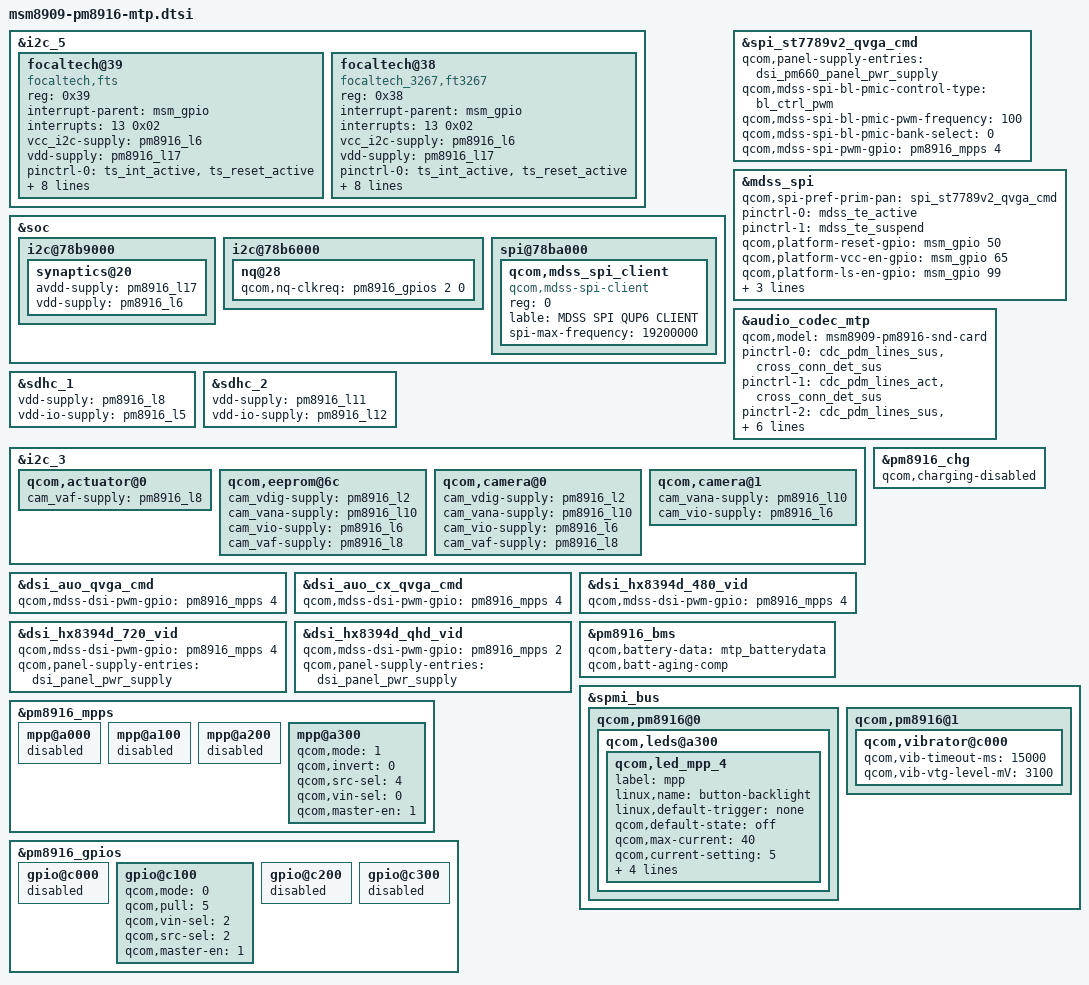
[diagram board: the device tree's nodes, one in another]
/*
 * Copyright (c) 2014-2017, The Linux Foundation. All rights reserved.
 *
 * This program is free software; you can redistribute it and/or modify
 * it under the terms of the GNU General Public License version 2 and
 * only version 2 as published by the Free Software Foundation.
 *
 * This program is distributed in the hope that it will be useful,
 * but WITHOUT ANY WARRANTY; without even the implied warranty of
 * MERCHANTABILITY or FITNESS FOR A PARTICULAR PURPOSE.  See the
 * GNU General Public License for more details.
 */

/*[Arima_4101][allen_yu] LightPhone ft3417 touch driver porting and dynamic detect ft3267 and ft3417 20181227 begin*/
/*[Arima_4101][allen_yu] LightPhone ft3267 touch driver porting 20180906 begin*/
&i2c_5 {
	status = "ok";
	focaltech@39 {
		compatible = "focaltech,fts";
		reg = <0x39>;
		interrupt-parent = <&msm_gpio>;
		interrupts = <13 0x02>;
		vcc_i2c-supply = <&pm8916_l6>;
		vdd-supply = <&pm8916_l17>;
		//focaltech,vcc_i2c-voltage = <1800000 1800000>;
		//focaltech,vdd-voltage = <2600000 3300000>;
		//focaltech,vcc_i2c-current = <40000>;
		//focaltech,vdd-current = <20000>;
		/* pins used by touchscreen */
		pinctrl-names = "pmx_ts_active", "pmx_ts_suspend",
			"pmx_ts_release";
		pinctrl-0 = <&ts_int_active &ts_reset_active>;
		pinctrl-1 = <&ts_int_suspend &ts_reset_suspend>;
		pinctrl-2 = <&ts_release>;
		focaltech,display-coords = <0 0 480 600>;
		focaltech,panel-coords = <0 0 480 600>;
		focaltech,irq-gpio = <&msm_gpio 13 0x02>;
		focaltech,reset-gpio = <&msm_gpio 25 0x01>;
		focaltech,max-touch-number = <5>;
		focaltech,i2c-pull-up;
		//focaltech,disable-gpios;
		//focaltech,button-map = <139 172 158>;
		};
};


&i2c_5 {
	status = "ok";
	focaltech@38 {
		compatible = "focaltech_3267,ft3267";
		reg = <0x38>;
		interrupt-parent = <&msm_gpio>;
		interrupts = <13 0x02>;
		vcc_i2c-supply = <&pm8916_l6>;
		vdd-supply = <&pm8916_l17>;
		//focaltech,vcc_i2c-voltage = <1800000 1800000>;
		//focaltech,vdd-voltage = <2600000 3300000>;
		//focaltech,vcc_i2c-current = <40000>;
		//focaltech,vdd-current = <20000>;
		/* pins used by touchscreen */
		pinctrl-names = "pmx_ts_active", "pmx_ts_suspend",
			"pmx_ts_release";
		pinctrl-0 = <&ts_int_active &ts_reset_active>;
		pinctrl-1 = <&ts_int_suspend &ts_reset_suspend>;
		pinctrl-2 = <&ts_release>;
/*[Arima_4101][allen_yu] Modify LCM/TP resolution 20181121 begin*/
		focaltech,display-coords = <0 0 480 600>;
		focaltech,panel-coords = <0 0 480 600>;
/*[Arima_4101][allen_yu] 20181121 end*/
		focaltech,irq-gpio = <&msm_gpio 13 0x02>;
		focaltech,reset-gpio = <&msm_gpio 25 0x01>;
/*[Arima_4101][allen_yu] Upgrade focaltech touch firmware to V12 20181017 begin*/
/*[Arima_4101][allen_yu] Fix multi touch issue(change protocal from B to A) 20181015 begin*/
		focaltech,max-touch-number = <1>;
/*[Arima_4101][allen_yu] 20181015 end*/
/*[Arima_4101][allen_yu] 20181017 end*/
		focaltech,i2c-pull-up;
		//focaltech,disable-gpios;
		//focaltech,button-map = <139 172 158>;
		};
};
/*[Arima_4101][allen_yu] 20180906 end*/
/*[Arima_4101][allen_yu] 20181227 end*/

&soc {
	i2c@78b9000 {
		synaptics@20 {
			avdd-supply = <&pm8916_l17>;
			vdd-supply = <&pm8916_l6>;
		};
	};

	i2c@78b6000 {
		nq@28 {
			qcom,nq-clkreq = <&pm8916_gpios 2 0>;
		};
	};

	spi@78ba000 {
		status = "ok";
		qcom,mdss_spi_client {
			reg = <0>;
			compatible = "qcom,mdss-spi-client";
			lable = "MDSS SPI QUP6 CLIENT";
			//spi-max-frequency = <50000000>;
			spi-max-frequency = <19200000>;
			//spi-cpha;
		};
	};
};

&spi_st7789v2_qvga_cmd {
		qcom,panel-supply-entries = <&dsi_pm660_panel_pwr_supply>;
		qcom,mdss-spi-bl-pmic-control-type = "bl_ctrl_pwm";
		qcom,mdss-spi-bl-pmic-pwm-frequency = <100>;
		qcom,mdss-spi-bl-pmic-bank-select = <0>;
		qcom,mdss-spi-pwm-gpio = <&pm8916_mpps 4 0>;
		/*qcom,cont-splash-enabled;*/
	};

&mdss_spi {
		qcom,spi-pref-prim-pan = <&spi_st7789v2_qvga_cmd>;
		pinctrl-names = "mdss_default", "mdss_sleep";
		pinctrl-0 = <&mdss_te_active>;
		pinctrl-1 = <&mdss_te_suspend>;
//[4101][Raymond]Display driver porting - begin
		//qcom,platform-te-gpio = <&msm_gpio 49 0>;
		qcom,platform-reset-gpio = <&msm_gpio 50 0>;
		qcom,platform-vcc-en-gpio = <&msm_gpio 65 0>;
//[4101][Raymond] decrease power consumption in suspend - begin		
		qcom,platform-ls-en-gpio = <&msm_gpio 99 0>;
		qcom,platform-boost-en-gpio = <&msm_gpio 76 0>;
//[4101][Raymond] decrease power consumption in suspend - end		
		//qcom,platform-spi-dc-gpio = <&msm_gpio 59 0>; 
		qcom,platform-busy-gpio = <&msm_gpio 49 0>;
//[4101][Raymond]Display driver porting - end
		//vdd-supply = <&pm8916_l7>;
		vddio-supply = <&pm8916_l5>;
	};

&audio_codec_mtp {
	qcom,model = "msm8909-pm8916-snd-card";
	pinctrl-names =
		"all_off",
		"pri_i2s_act",
		"us_eu_gpio_act",
		"pri_i2s_us_eu_gpio_act";
	pinctrl-0 = <&cdc_pdm_lines_sus &cross_conn_det_sus>;
	pinctrl-1 = <&cdc_pdm_lines_act &cross_conn_det_sus>;
	pinctrl-2 = <&cdc_pdm_lines_sus &cross_conn_det_act>;
	pinctrl-3 = <&cdc_pdm_lines_act &cross_conn_det_act>;
	asoc-codec = <&stub_codec>, <&pm8916_tombak_dig>;
	asoc-codec-names = "msm-stub-codec.1", "cajon_codec";
};

&sdhc_1 {
	vdd-supply = <&pm8916_l8>;
	vdd-io-supply = <&pm8916_l5>;
};

&sdhc_2 {
	vdd-supply = <&pm8916_l11>;
	vdd-io-supply = <&pm8916_l12>;
};

&i2c_3 {
	qcom,actuator@0 {
		cam_vaf-supply = <&pm8916_l8>;
	};


	qcom,eeprom@6c{
		cam_vdig-supply = <&pm8916_l2>;
		cam_vana-supply = <&pm8916_l10>;
		cam_vio-supply = <&pm8916_l6>;
		cam_vaf-supply = <&pm8916_l8>;
	};

	qcom,camera@0 {
		cam_vdig-supply = <&pm8916_l2>;
		cam_vana-supply = <&pm8916_l10>;
		cam_vio-supply = <&pm8916_l6>;
		cam_vaf-supply = <&pm8916_l8>;
	};

	qcom,camera@1 {
		cam_vana-supply = <&pm8916_l10>;
		cam_vio-supply = <&pm8916_l6>;
	};
};

&dsi_auo_qvga_cmd {
	qcom,mdss-dsi-pwm-gpio = <&pm8916_mpps 4 0>;
};

&dsi_auo_cx_qvga_cmd {
	qcom,mdss-dsi-pwm-gpio = <&pm8916_mpps 4 0>;
};
&dsi_hx8394d_480_vid {
	qcom,mdss-dsi-pwm-gpio = <&pm8916_mpps 4 0>;
};

&dsi_hx8394d_720_vid {
	qcom,mdss-dsi-pwm-gpio = <&pm8916_mpps 4 0>;
	qcom,panel-supply-entries = <&dsi_panel_pwr_supply>;
};

&dsi_hx8394d_qhd_vid {
	qcom,mdss-dsi-pwm-gpio = <&pm8916_mpps 2 0>;
	qcom,panel-supply-entries = <&dsi_panel_pwr_supply>;
};


&pm8916_chg {
	status = "ok";
	qcom,charging-disabled;
};

&pm8916_bms {
	status = "ok";
	qcom,battery-data = <&mtp_batterydata>;
	qcom,batt-aging-comp;
};

&spmi_bus {
	qcom,pm8916@0 {
		qcom,leds@a300 {
			status = "okay";
			qcom,led_mpp_4 {
				label = "mpp";
				linux,name = "button-backlight";
				linux,default-trigger = "none";
				qcom,default-state = "off";
				qcom,max-current = <40>;
				qcom,current-setting = <5>;
				qcom,id = <6>;
				qcom,mode = "manual";
				qcom,source-sel = <1>;
				qcom,mode-ctrl = <0x60>;
			};
		};
	};

	qcom,pm8916@1 {
		qcom,vibrator@c000 {
			status = "okay";
			qcom,vib-timeout-ms = <15000>;
			qcom,vib-vtg-level-mV = <3100>;
		};
	};
};

&pm8916_mpps {
	mpp@a000 { /* MPP 1 */
		/* VDD_PX */
		status = "disabled";
	};

	mpp@a100 { /* MPP 2 */
		/* HR LED */
		status = "disabled";
	};

	mpp@a200 { /* MPP 3 */
		/* VREF DAC */
		status = "disabled";
	};

	mpp@a300 { /* MPP 4 */
		/* Backlight PWM */
		qcom,mode = <1>;		/* Digital output */
		qcom,invert = <0>;		/* Disable invert */
		qcom,src-sel = <4>;		/* DTEST1 */
		qcom,vin-sel = <0>;		/* VPH_PWR */
		qcom,master-en = <1>;		/* Enable MPP */
	};
};

&pm8916_gpios {
	gpio@c000 { /* GPIO 1 */
		/* Battery UICC Alarm */
		status = "disabled";
	};

	gpio@c100 { /* GPIO 2 */
		/* NFC_CLK_REQ */
		qcom,mode = <0>; /* QPNP_PIN_MODE_DIG_IN */
		qcom,pull = <5>; /* QPNP_PIN_PULL_NO */
		qcom,vin-sel = <2>; /* QPNP_PIN_VIN2 */
		qcom,src-sel = <2>; /* QPNP_PIN_SEL_FUNC_1 */
		qcom,master-en = <1>;
	};

	gpio@c200 { /* GPIO 3 */
		/* External regulator control for WTR */
		status = "disabled";
	};

	gpio@c300 { /* GPIO 4 */
		/* External regulator control for APC */
		status = "disabled";
	};
};

